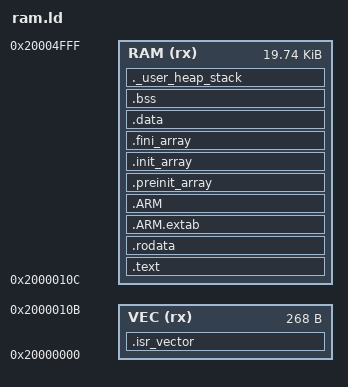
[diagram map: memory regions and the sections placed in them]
/*--------------------------------------------------------------------------------
  File: stm32f103c8.ld from STM32CubeMX
  See License and copyright at bottom
*/

/* Entry Point */
ENTRY(Reset_Handler)

/* need space for vector table at 0x20000000 67 4 byte entries */
_vector_table_size = 67*4;

/* Generate a link error if heap and stack don't fit into RAM */
_Min_Heap_Size = 0K;    /* required amount of heap  */
_Min_Stack_Size = 1K;   /* required amount of stack */

/* Highest address of the user mode stack */
_estack = 0x20005000;  /* top of stack */

/* Specify the memory areas */
MEMORY
{
  VEC (rx) : ORIGIN = 0x20000000, LENGTH = 67*4
  RAM (rx) : ORIGIN = 0x20000000+(67*4), LENGTH = 20K-(67*4)
}

/* Define output sections */
SECTIONS
{
  /* The vector table goes first into RAM must be at 0x08000000 */
  .isr_vector :
  {
    . = ALIGN(4);
    KEEP(*(.isr_vector)) /* intial stack address and ISR vector table */
    . = ALIGN(4);
  } >VEC

  /* The program code and other data goes into RAM */
  .text :
  {
    . = ALIGN(4);
    *(.text)           /* .text sections (code) */
    *(.text*)          /* .text* sections (code) */
    *(.glue_7)         /* glue arm to thumb code - never used on cortex-m3  */
    *(.glue_7t)        /* glue thumb to arm code - never used on cortex-m3 */
    *(.eh_frame)       /* only used with c++ exceptions - likely not used */

    KEEP (*(.init))
    KEEP (*(.fini))

    . = ALIGN(4);
    _etext = .;        /* define a global symbols at end of code */
  } >RAM

  /* Constant data goes into RAM */
  .rodata :
  {
    . = ALIGN(4);
    *(.rodata)         /* .rodata sections (constants, strings, etc.) */
    *(.rodata*)        /* .rodata* sections (constants, strings, etc.) */
    . = ALIGN(4);
  } >RAM

  .ARM.extab   : { *(.ARM.extab* .gnu.linkonce.armextab.*) } >RAM
  .ARM : {
    __exidx_start = .;
    *(.ARM.exidx*)
    __exidx_end = .;
  } >RAM

  /* run before any C/C++ constructors */
  .preinit_array     :
  {
    PROVIDE_HIDDEN (__preinit_array_start = .);
    KEEP (*(.preinit_array*))
    PROVIDE_HIDDEN (__preinit_array_end = .);
  } >RAM

  /* C/C++ global constructors */
  .init_array :
  {
    PROVIDE_HIDDEN (__init_array_start = .);
    KEEP (*(SORT(.init_array.*)))
    KEEP (*(.init_array*))
    PROVIDE_HIDDEN (__init_array_end = .);
  } >RAM

  /* C/C++ global destructors */
  .fini_array :
  {
    PROVIDE_HIDDEN (__fini_array_start = .);
    KEEP (*(SORT(.fini_array.*)))
    KEEP (*(.fini_array*))
    PROVIDE_HIDDEN (__fini_array_end = .);
  } >RAM

  /* Initialized data sections goes into RAM, load LMA copy after code */
  .data : 
  {
    . = ALIGN(4);
   _sidata = LOADADDR(.data); /* used by the startup to initialize data */
    _sdata = .;               /* create a global symbol at data start */
    *(.data)                  /* .data sections */
    *(.data*)                 /* .data* sections */
    . = ALIGN(4);
    _edata = .;               /* define a global symbol at data end */
    _data_len = _edata - _sdata; 
  } >RAM AT> RAM

  /* Uninitialized data section */
  .bss :
  {
    /* This is used by the startup in order to initialize the .bss secion */
    . = ALIGN(4);
    _sbss = .;         /* define a global symbol at bss start */
    __bss_start__ = _sbss;
    *(.bss)
    *(.bss*)
    *(COMMON)
    . = ALIGN(4);
    _ebss = .;         /* define a global symbol at bss end */
    __bss_end__ = _ebss;
    __bss_len = _ebss - _sbss;
  } >RAM

  /* User_heap_stack section, used to check that there is enough RAM left */
  ._user_heap_stack :
  {
    . = ALIGN(4);     /* original used 8, for fp stack align? cm3 no fp hw */
    PROVIDE ( end = . );
    PROVIDE ( _end = . );
    . = . + _Min_Heap_Size;
    . = . + _Min_Stack_Size;
    . = ALIGN(4);
  } >RAM

  /* Remove information from the standard libraries */
  /DISCARD/ :
  {
    libc.a ( * )
    libm.a ( * )
    libgcc.a ( * )
  }

  .ARM.attributes 0 : { *(.ARM.attributes) }
}

PROVIDE(_sstack   = ORIGIN(RAM)+LENGTH(RAM)-_Min_Stack_Size);
PROVIDE(_ram_size = ORIGIN(RAM)+LENGTH(RAM));
PROVIDE(_end_heap = ORIGIN(RAM)+LENGTH(RAM)-_Min_Stack_Size);


/*
******************************************************************************
**
**  File        : LinkerScript.ld
**
**  Author      : Auto-generated by Ac6 System Workbench
**
**  Abstract    : Linker script for STM32F103C8Tx series
**                0Kbytes FLASH and 20Kbytes RAM
**
**                Set heap size, stack size and stack location according
**                to application requirements.
**
**                Set memory bank area and size if external memory is used.
**
**  Target      : STMicroelectronics STM32
**
**  Distribution: The file is distributed “as is,” without any warranty
**                of any kind.
**
*****************************************************************************
** @attention
**
** <h2><center>&copy; COPYRIGHT(c) 2014 Ac6</center></h2>
**
** Redistribution and use in source and binary forms, with or without modification,
** are permitted provided that the following conditions are met:
**   1. Redistributions of source code must retain the above copyright notice,
**      this list of conditions and the following disclaimer.
**   2. Redistributions in binary form must reproduce the above copyright notice,
**      this list of conditions and the following disclaimer in the documentation
**      and/or other materials provided with the distribution.
**   3. Neither the name of Ac6 nor the names of its contributors
**      may be used to endorse or promote products derived from this software
**      without specific prior written permission.
**
** THIS SOFTWARE IS PROVIDED BY THE COPYRIGHT HOLDERS AND CONTRIBUTORS "AS IS"
** AND ANY EXPRESS OR IMPLIED WARRANTIES, INCLUDING, BUT NOT LIMITED TO, THE
** IMPLIED WARRANTIES OF MERCHANTABILITY AND FITNESS FOR A PARTICULAR PURPOSE ARE
** DISCLAIMED. IN NO EVENT SHALL THE COPYRIGHT HOLDER OR CONTRIBUTORS BE LIABLE
** FOR ANY DIRECT, INDIRECT, INCIDENTAL, SPECIAL, EXEMPLARY, OR CONSEQUENTIAL
** DAMAGES (INCLUDING, BUT NOT LIMITED TO, PROCUREMENT OF SUBSTITUTE GOODS OR
** SERVICES; LOSS OF USE, DATA, OR PROFITS; OR BUSINESS INTERRUPTION) HOWEVER
** CAUSED AND ON ANY THEORY OF LIABILITY, WHETHER IN CONTRACT, STRICT LIABILITY,
** OR TORT (INCLUDING NEGLIGENCE OR OTHERWISE) ARISING IN ANY WAY OUT OF THE USE
** OF THIS SOFTWARE, EVEN IF ADVISED OF THE POSSIBILITY OF SUCH DAMAGE.
**
*****************************************************************************
*/
/* vim: set ts=2 sw=2 expandtab: */
